# MCXA153 register map
Vendor: nxp.com; File version: 1.0
CPU: CM33 r2p0, little endian, no MPU, no FPU, VTOR, 3 interrupt priority bits
Registers are 32-bit, read-write, reset 0x0 unless marked. A register's access mark holds for its fields unless they carry their own. Offsets are from the block's base; [hi:lo] are bit positions.

## EIM0 — EIM
Base 0x4008C000
0x00 EIMCR — Error Injection Module Configuration Register
  [0] GEIEN — Global Error Injection Enable
    0=DISABLE (Disabled); 1=ENABLE (Enabled)
0x04 EICHEN — Error Injection Channel Enable register
  [31] EICH0EN — Error Injection Channel 0 Enable
    0=DISABLE (Error injection is disabled on Error Injection Channel 0); 1=ENABLE (Error injection is enabled on Error Injection Channel 0)
0x100 EICHD0_WORD0 — Error Injection Channel Descriptor 0, Word0
  [31:25] CHKBIT_MASK — Checkbit Mask
0x104 EICHD0_WORD1 — Error Injection Channel Descriptor 0, Word1
  [31:0] B0_3DATA_MASK — Data Mask Bytes 0-3

## ERM0 — ERM
Base 0x4008D000
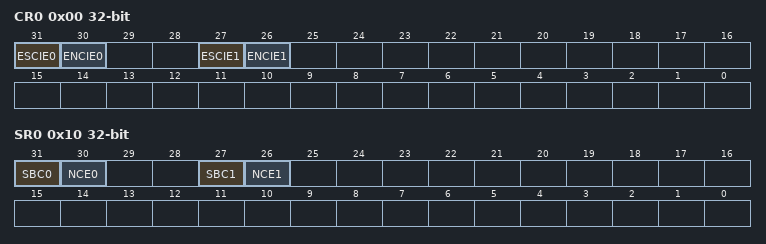
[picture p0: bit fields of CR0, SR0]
0x00 CR0 — ERM Configuration Register 0
  [31] ESCIE0
    0=DISABLE (Interrupt notification of Memory 0 single-bit correction events is disabled.); 1=ENABLE (Interrupt notification of Memory 0 single-bit correction events is enabled.)
  [30] ENCIE0
    0=DISABLE (Interrupt notification of Memory 0 non-correctable error events is disabled.); 1=ENABLE (Interrupt notification of Memory 0 non-correctable error events is enabled.)
  [27] ESCIE1
    0=DISABLE (Interrupt notification of Memory 1 single-bit correction events is disabled.); 1=ENABLE (Interrupt notification of Memory 1 single-bit correction events is enabled.)
  [26] ENCIE1
    0=DISABLE (Interrupt notification of Memory 1 non-correctable error events is disabled.); 1=ENABLE (Interrupt notification of Memory 1 non-correctable error events is enabled.)
0x10 SR0 write-1-clears — ERM Status Register 0
  [31] SBC0 write-1-clears
    0=NO_EVENT (No single-bit correction event on Memory 0 detected.); 1=EVENT (Single-bit correction event on Memory 0 detected.)
  [30] NCE0 write-1-clears
    0=NO_ERROR (No non-correctable error event on Memory 0 detected.); 1=ERROR (Non-correctable error event on Memory 0 detected.)
  [27] SBC1 write-1-clears
    0=NO_EVENT (No single-bit correction event on Memory 1 detected.); 1=EVENT (Single-bit correction event on Memory 1 detected.)
  [26] NCE1 write-1-clears
    0=NO_ERROR (No non-correctable error event on Memory 1 detected.); 1=ERROR (Non-correctable error event on Memory 1 detected.)
0x100 EAR0 ro — ERM Memory 0 Error Address Register
  [31:0] EAR
0x104 SYN0 ro — ERM Memory 0 Syndrome Register
  [31:24] SYNDROME
0x108 CORR_ERR_CNT0 — ERM Memory 0 Correctable Error Count Register
  [7:0] COUNT — Memory n Correctable Error Count
0x118 CORR_ERR_CNT1 — ERM Memory 1 Correctable Error Count Register
  [7:0] COUNT — Memory n Correctable Error Count

## GLIKEY0 — GLIKEY
Base 0x40091D00
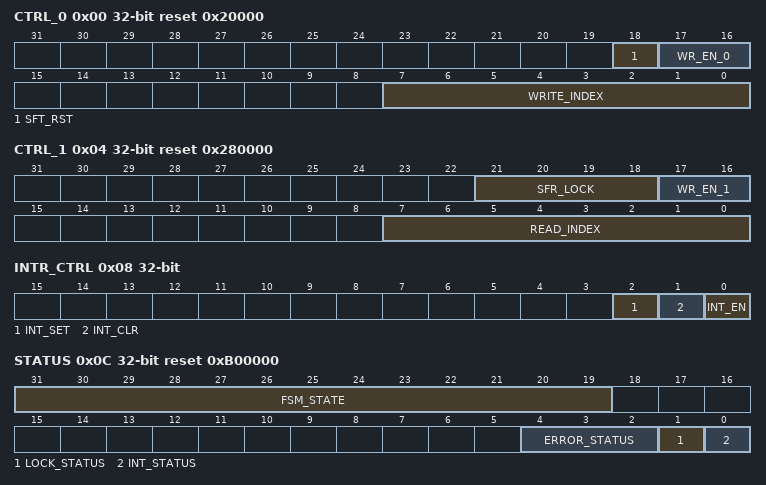
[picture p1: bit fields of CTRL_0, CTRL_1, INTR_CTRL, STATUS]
0x00 CTRL_0 reset 0x20000 — Control Register 0 SFR
  [18] SFT_RST — Soft reset for the core reset (SFR configuration will be preseved).This register reads as 0
    0=DISABLE (No effect); 1=ENABLE (Triggers the soft reset)
  [17:16] WR_EN_0 — Write Enable 0
  [7:0] WRITE_INDEX
0x04 CTRL_1 reset 0x280000 — Control Regsiter 1 SFR
  [21:18] SFR_LOCK — LOCK register for GLIKEY
  [17:16] WR_EN_1 — Write Enable One
  [7:0] READ_INDEX — Index status, Writing an index value to this register will request the block to return the lock status of this index.
0x08 INTR_CTRL — Interrupt Control
  [2] INT_SET — Interrupt Set. Writing a 1 to this register asserts the interrupt. This register reads as 0
    0=DISABLE (No effect); 1=ENABLE (Triggers interrupt)
  [1] INT_CLR — Interrupt Clear. Writing a 1 to this register creates a single interrupt clear pulse. This register reads as 0
  [0] INT_EN — Interrupt Enable. Writing a 1, Interrupt asserts on Interrupt output port
0x0C STATUS ro reset 0xB00000
  [31:19] FSM_STATE — Status of FSM
  [4:2] ERROR_STATUS — Status of the Error
    0=STAT0 (No error); 1=STAT1 (FSM error has occurred); 2=STAT2 (Write index out of the bound (OOB) error); 3=STAT3 (Write index OOB and FSM error); 4=STAT4 (Read index OOB error); 6=STAT5 (Write index and read index OOB error); 7=STAT6 (Read index OOB, write index OOB, and FSM error)
  [1] LOCK_STATUS — Provides the current lock status of indexes.
    0=LOCK0 (Current read index is not locked); 1=LOCK1 (Current read index is locked)
  [0] INT_STATUS — Interrupt Status.
    0=DISABLE (No effect); 1=ENABLE (Triggers interrupt)
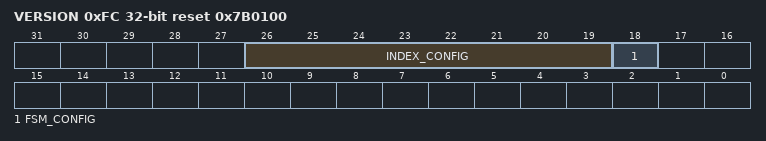
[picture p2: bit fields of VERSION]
0xFC VERSION ro reset 0x7B0100 — IP Version
  [26:19] INDEX_CONFIG — Configured number of addressable indexes
  [18] FSM_CONFIG — 0:4 step, 1:8 step

## Notices in the file
Copyright 2016-2024 NXP
SPDX-License-Identifier: BSD-3-Clause
